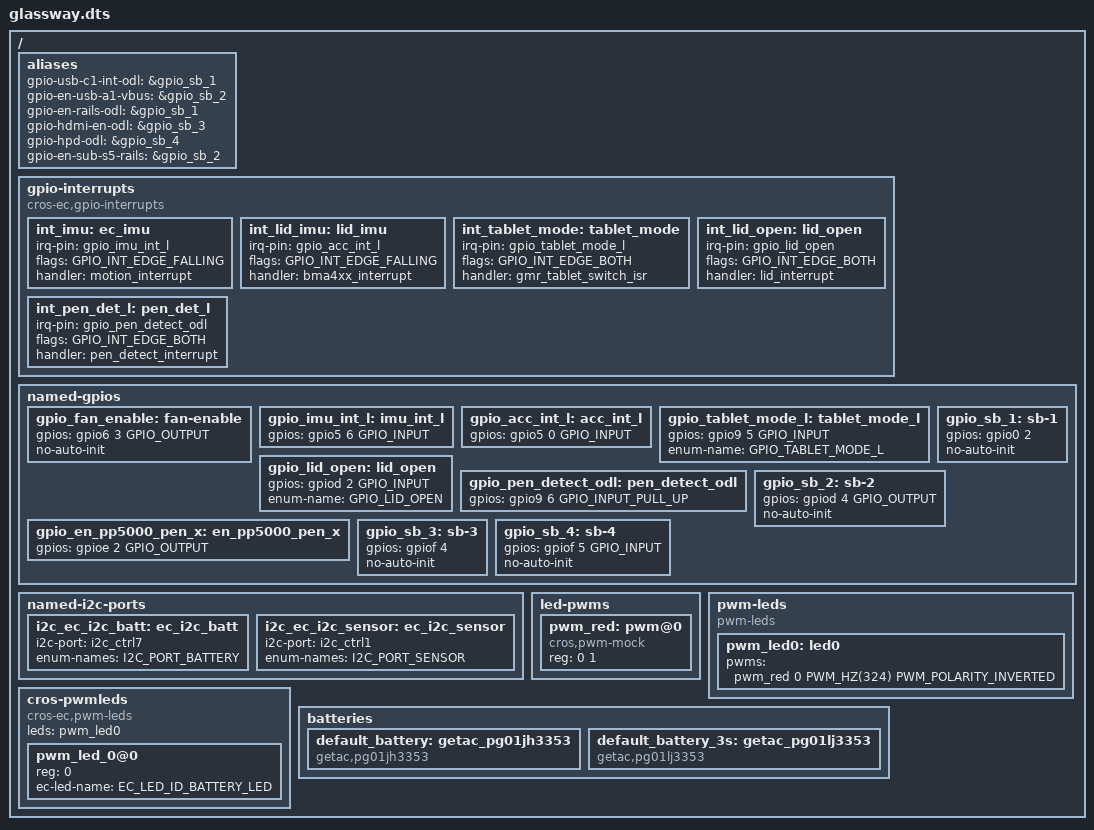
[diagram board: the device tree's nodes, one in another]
/* Copyright 2024 The ChromiumOS Authors
 * Use of this source code is governed by a BSD-style license that can be
 * found in the LICENSE file.
 */

#include <dt-bindings/pwm/pwm.h>

#include "../program/nissa/glassway/cbi.dtsi"
#include "../program/nissa/glassway/motionsense.dtsi"

/ {
        aliases {
                /* type-C */
                gpio-usb-c1-int-odl = &gpio_sb_1;
                /* type-A */
                gpio-en-usb-a1-vbus = &gpio_sb_2;
                /* HDMI */
                gpio-en-rails-odl = &gpio_sb_1;
                gpio-hdmi-en-odl = &gpio_sb_3;
                gpio-hpd-odl = &gpio_sb_4;
                /* LTE */
                gpio-en-sub-s5-rails = &gpio_sb_2;
        };

	gpio-interrupts {
		compatible = "cros-ec,gpio-interrupts";
		int_imu: ec_imu {
                        irq-pin = <&gpio_imu_int_l>;
                        flags = <GPIO_INT_EDGE_FALLING>;
                        handler = "motion_interrupt";
                };
                int_lid_imu: lid_imu {
                        irq-pin = <&gpio_acc_int_l>;
                        flags = <GPIO_INT_EDGE_FALLING>;
                        handler = "bma4xx_interrupt";
                };
                int_tablet_mode: tablet_mode {
                        irq-pin = <&gpio_tablet_mode_l>;
                        flags = <GPIO_INT_EDGE_BOTH>;
                        handler = "gmr_tablet_switch_isr";
                };
                int_lid_open: lid_open {
                        irq-pin = <&gpio_lid_open>;
			flags = <GPIO_INT_EDGE_BOTH>;
                        handler = "lid_interrupt";
                };
		int_pen_det_l: pen_det_l {
			irq-pin = <&gpio_pen_detect_odl>;
                        flags = <GPIO_INT_EDGE_BOTH>;
                        handler = "pen_detect_interrupt";
                };
	};

	named-gpios {
		gpio_fan_enable: fan-enable {
			gpios = <&gpio6 3 GPIO_OUTPUT>;
			no-auto-init;
		};
		gpio_imu_int_l: imu_int_l {
                        gpios = <&gpio5 6 GPIO_INPUT>;
                };
                gpio_acc_int_l: acc_int_l {
                        gpios = <&gpio5 0 GPIO_INPUT>;
                };
                gpio_tablet_mode_l: tablet_mode_l {
                        gpios = <&gpio9 5 GPIO_INPUT>;
                        enum-name = "GPIO_TABLET_MODE_L";
                };
                gpio_lid_open: lid_open {
                        gpios = <&gpiod 2 GPIO_INPUT>;
                        enum-name = "GPIO_LID_OPEN";
                };
		gpio_pen_detect_odl: pen_detect_odl {
                        gpios = <&gpio9 6 GPIO_INPUT_PULL_UP>;
                };
                gpio_en_pp5000_pen_x: en_pp5000_pen_x {
                        gpios = <&gpioe 2 GPIO_OUTPUT>;
                };
                gpio_sb_1: sb-1 {
                        gpios = <&gpio0 2 GPIO_PULL_UP>;
                        no-auto-init;
                };

                gpio_sb_2: sb-2 {
                        gpios = <&gpiod 4 GPIO_OUTPUT>;
                        no-auto-init;
                };

                gpio_sb_3: sb-3 {
                        gpios = <&gpiof 4 0>;
                        no-auto-init;
                };

                gpio_sb_4: sb-4 {
                        gpios = <&gpiof 5 GPIO_INPUT>;
                        no-auto-init;
                };
	};

	named-i2c-ports {
		i2c_ec_i2c_batt: ec_i2c_batt {
			i2c-port = <&i2c_ctrl7>;
			enum-names = "I2C_PORT_BATTERY";
		};
		i2c_ec_i2c_sensor: ec_i2c_sensor {
			i2c-port = <&i2c_ctrl1>;
			enum-names = "I2C_PORT_SENSOR";
		};
	};

	/* LEDs need to exist for testing, but aren't actually used. */
	led-pwms {
		#address-cells = <1>;
		#size-cells = <1>;

		pwm_red: pwm@0 {
			compatible = "cros,pwm-mock";
			reg = <0 1>;
			#pwm-cells = <3>;
		};
	};

	pwm-leds {
		compatible = "pwm-leds";

		pwm_led0: led0 {
			pwms = <&pwm_red 0 PWM_HZ(324) PWM_POLARITY_INVERTED>;
		};
	};

	cros-pwmleds {
		compatible = "cros-ec,pwm-leds";
		leds = <&pwm_led0>;

		#address-cells = <1>;
		#size-cells = <0>;

		pwm_led_0@0 {
			reg = <0>;
			ec-led-name = "EC_LED_ID_BATTERY_LED";
		};
	};

	batteries {
		default_battery: getac_pg01jh3353 {
			compatible = "getac,pg01jh3353", "battery-smart";
		};
		default_battery_3s: getac_pg01lj3353 {
			compatible = "getac,pg01lj3353", "battery-smart";
		};
	};
};
